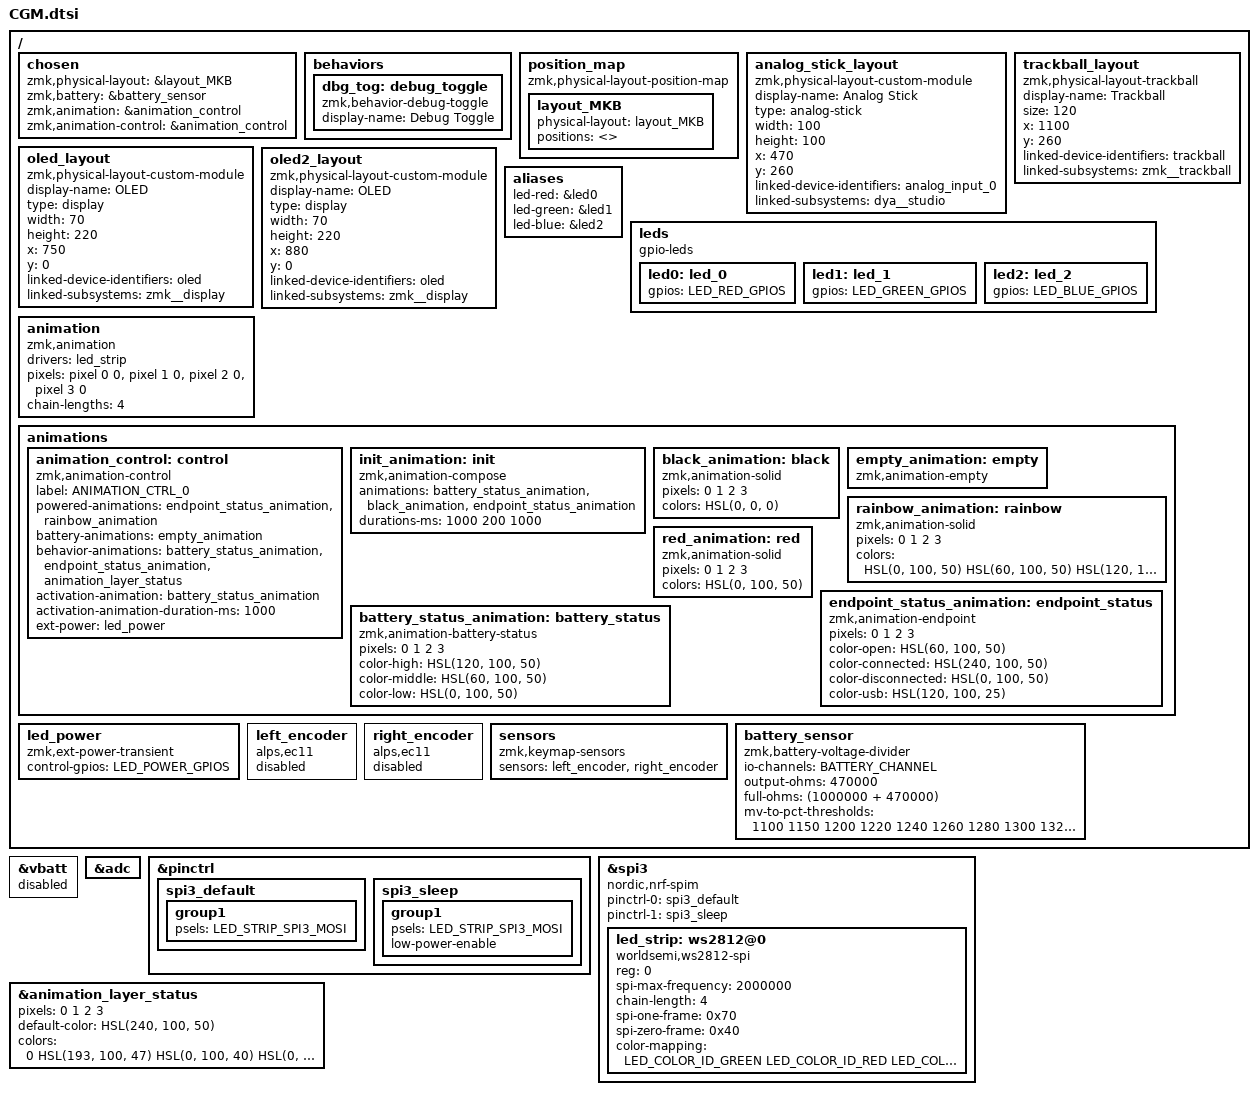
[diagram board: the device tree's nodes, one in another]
#include <behaviors/animation_trigger.dtsi>
#include <behaviors/animation_control.dtsi>
#include <dt-bindings/led/led.h>
#include <dt-bindings/zmk_driver_animation/animation_control.h>
#include <dt-bindings/zmk_driver_animation/animation_trigger.h>
#include <zmk_driver_animation/animation.dtsi>
#include <zmk_driver_animation/animation_layer_status.dtsi>

#include "CGM-layout.dtsi"
#include <behaviors/rgbled_widget.dtsi>
/ {
	chosen {
		zmk,physical-layout = &layout_MKB;
   		zmk,battery = &battery_sensor;
		zmk,animation = &animation_control;
		zmk,animation-control = &animation_control;
	};

	behaviors {
		dbg_tog: debug_toggle {
			compatible = "zmk,behavior-debug-toggle";
			#binding-cells = <0>;
			display-name = "Debug Toggle";
		};
	};


	position_map {
		compatible = "zmk,physical-layout-position-map";

		layout_MKB {
			physical-layout = <&layout_MKB>;
			positions = <>;
		};
	};

	analog_stick_layout: analog_stick_layout {
		compatible = "zmk,physical-layout-custom-module";
		display-name = "Analog Stick";
		type = "analog-stick";
		width = <100>;
		height = <100>;
		x = <470>;
		y = <260>;
		linked-device-identifiers = "analog_input_0";
		linked-subsystems = "dya__studio";
	};

	trackball_layout: trackball_layout {
		compatible = "zmk,physical-layout-trackball";
		display-name = "Trackball";
		size = <120>;
		x = <1100>;
		y = <260>;
		linked-device-identifiers = "trackball";
		linked-subsystems = "zmk__trackball";
	};

	oled_layout: oled_layout {
		compatible = "zmk,physical-layout-custom-module";
		display-name = "OLED";
		type = "display";
		width = <70>;
		height = <220>;
		x = <750>;
		y = <0>;
		linked-device-identifiers = "oled";
		linked-subsystems = "zmk__display";
	};
	
	oled2_layout: oled2_layout {
		compatible = "zmk,physical-layout-custom-module";
		display-name = "OLED";
		type = "display";
		width = <70>;
		height = <220>;
		x = <880>;
		y = <0>;
		linked-device-identifiers = "oled";
		linked-subsystems = "zmk__display";
	};

	aliases {
		led-red = &led0;
		led-green = &led1;
		led-blue = &led2;
	};

	leds {
		compatible = "gpio-leds";
		status = "okay";
		led0: led_0 {
		gpios = LED_RED_GPIOS;
		};
		led1: led_1 {
		gpios = LED_GREEN_GPIOS;
		};
		led2: led_2 {
		gpios = LED_BLUE_GPIOS;
		};
	};


	animation: animation {
		compatible = "zmk,animation";
		drivers = <&led_strip>;
		pixels = <&pixel 0 0>,
		<&pixel 1 0>,
		<&pixel 2 0>,
		<&pixel 3 0>;
		chain-lengths = <4>;
	};
	
	animations {
		/omit-if-no-ref/ animation_control: control {
			compatible = "zmk,animation-control";
			label = "ANIMATION_CTRL_0";
			powered-animations = <&endpoint_status_animation &rainbow_animation>;
			battery-animations = <&empty_animation>;
			behavior-animations = <&battery_status_animation &endpoint_status_animation &animation_layer_status>;
			activation-animation = <&battery_status_animation>;
			activation-animation-duration-ms = <1000>;
			ext-power = <&led_power>;
		};
		/omit-if-no-ref/ init_animation: init {
			compatible = "zmk,animation-compose";
			animations = <&battery_status_animation &black_animation &endpoint_status_animation>;
			durations-ms = <1000 200 1000>;
		};
		/omit-if-no-ref/ black_animation: black {
			compatible = "zmk,animation-solid";
			pixels = <0 1 2 3>;
			colors = <HSL(0, 0, 0)>;
		};
		
		/omit-if-no-ref/ empty_animation: empty {
			compatible = "zmk,animation-empty";
			status = "okay";
		};
		/omit-if-no-ref/ rainbow_animation: rainbow {
			compatible = "zmk,animation-solid";
			status = "okay";
			pixels = <0 1 2 3>;
			colors = <HSL(0, 100, 50) HSL(60, 100, 50) HSL(120, 100, 50) HSL(180, 100, 50) HSL(240, 100, 50) HSL(300, 100, 50)>;
		};
		/omit-if-no-ref/ red_animation: red {
			compatible = "zmk,animation-solid";
			status = "okay";
			pixels = <0 1 2 3>;
			colors = <HSL(0, 100, 50)>;
		};
		/omit-if-no-ref/ endpoint_status_animation: endpoint_status {
			compatible = "zmk,animation-endpoint";
			status = "okay";
			pixels = <0 1 2 3>;
			color-open = <HSL(60, 100, 50)>;
			color-connected = <HSL(240, 100, 50)>;
			color-disconnected = <HSL(0, 100, 50)>;
			color-usb = <HSL(120, 100, 25)>;
		};
		/omit-if-no-ref/ battery_status_animation: battery_status {
			compatible = "zmk,animation-battery-status";
			status = "okay";
			pixels = <0 1 2 3>;
			color-high = <HSL(120, 100, 50)>;// green
			color-middle = <HSL(60, 100, 50)>;// yellow
			color-low = <HSL(0, 100, 50)>;// red
		};
	};
   

	led_power:led_power {
		compatible = "zmk,ext-power-transient";
		control-gpios = LED_POWER_GPIOS;
	};

   // Encoders
   left_encoder: left_encoder {
      compatible = "alps,ec11";
      status = "disabled";
   };

   right_encoder: right_encoder {
      compatible = "alps,ec11";
      status = "disabled";
   };

   sensors: sensors {
      compatible = "zmk,keymap-sensors";
      sensors = <&left_encoder &right_encoder>;
   };

    battery_sensor: battery_sensor {
        compatible = "zmk,battery-voltage-divider";
        io-channels = BATTERY_CHANNEL;
        output-ohms = <470000>;
        full-ohms = <(1000000 + 470000)>;
        // For Ni-Mh 1U
        mv-to-pct-thresholds = <1100 1150 1200 1220 1240 1260 1280 1300 1320 1350 1400>;
    };
};

&vbatt {
    status = "disabled";
};

&adc {
   status = "okay";
};

//
// pinctrl for LED strip (WS2812 2020)
//

&pinctrl {
	spi3_default: spi3_default {
		group1 {
			psels = <LED_STRIP_SPI3_MOSI>;
		};
	};
	
	spi3_sleep: spi3_sleep {
		group1 {
			psels = <LED_STRIP_SPI3_MOSI>;
			low-power-enable;
		};
	};
};

&spi3 {
	compatible = "nordic,nrf-spim";
	status = "okay";
	
	pinctrl-0 = <&spi3_default>;
	pinctrl-1 = <&spi3_sleep>;
	pinctrl-names = "default", "sleep";
	
	led_strip: ws2812@0 {
		compatible = "worldsemi,ws2812-spi";
		reg = <0>;
		// Note: Frequency should be between 2.5MHz to 5MHz
		// 2.5MHz := 1sec / 0.4us
		//           where 0.4us is min (T0H max, T0L max, T1H max, T1L max)
		//                 T0H max = 0.4us, T1H max = 1.0us, T0L,T1L max = 20us
		// 5MHz := min(1sec / 0.2us, 1sec / 1.2us * 8bit)
		//           where 0.2us is min (T0H min, T0L min, T1H min, T1L min)
		//                               T0H min = 0.2us, T1L min = 0.2us, T1H min = 0.58us, T0L min = 0.8us
		//                 1.2us is T min
		//                 8bit is because this driver builds 1frame with 8bit (spi-one-frame, spi-zero-frame)
		spi-max-frequency = <2000000>;// 4MHz = 0.25us
		
		chain-length = <4>; /* number of LEDs */
		spi-one-frame = <0x70>;// 01110000 -> T1H = 0.25 * 3 = 0.75us is between 0.58 and 1.0
		spi-zero-frame = <0x40>;// 01000000 -> T0H = 0.25us is between 0.2 and 0.4
		color-mapping = <LED_COLOR_ID_GREEN
		LED_COLOR_ID_RED
		LED_COLOR_ID_BLUE>;
	};
};

&animation_layer_status {
	pixels = <0 1 2 3>;
	default-color = <HSL(240, 100, 50)>;
	// default
	// windows blue
	// mac red
	// ios white
	// linux orange
	colors = <
	0
	HSL(193, 100, 47)
	HSL(0, 100, 40)
	HSL(0, 100, 100)
	HSL(29, 88, 51)
	>;
};
